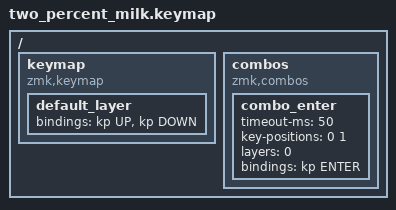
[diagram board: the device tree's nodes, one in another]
#include <behaviors.dtsi>
#include <dt-bindings/zmk/keys.h>
/ {
    keymap {
        compatible = "zmk,keymap";
        default_layer {
            // Left key, Right key
            bindings = <&kp UP &kp DOWN>;
        };
    };

    combos {
        compatible = "zmk,combos";

        // Press Left+Right together -> Enter
        combo_enter {
            timeout-ms = <50>;          // try 30–70ms if you want a different feel
            key-positions = <0 1>;      // position 0 = left key, 1 = right key
            layers = <0>;                // only on the default layer
            bindings = <&kp ENTER>;
        };
    };
};
